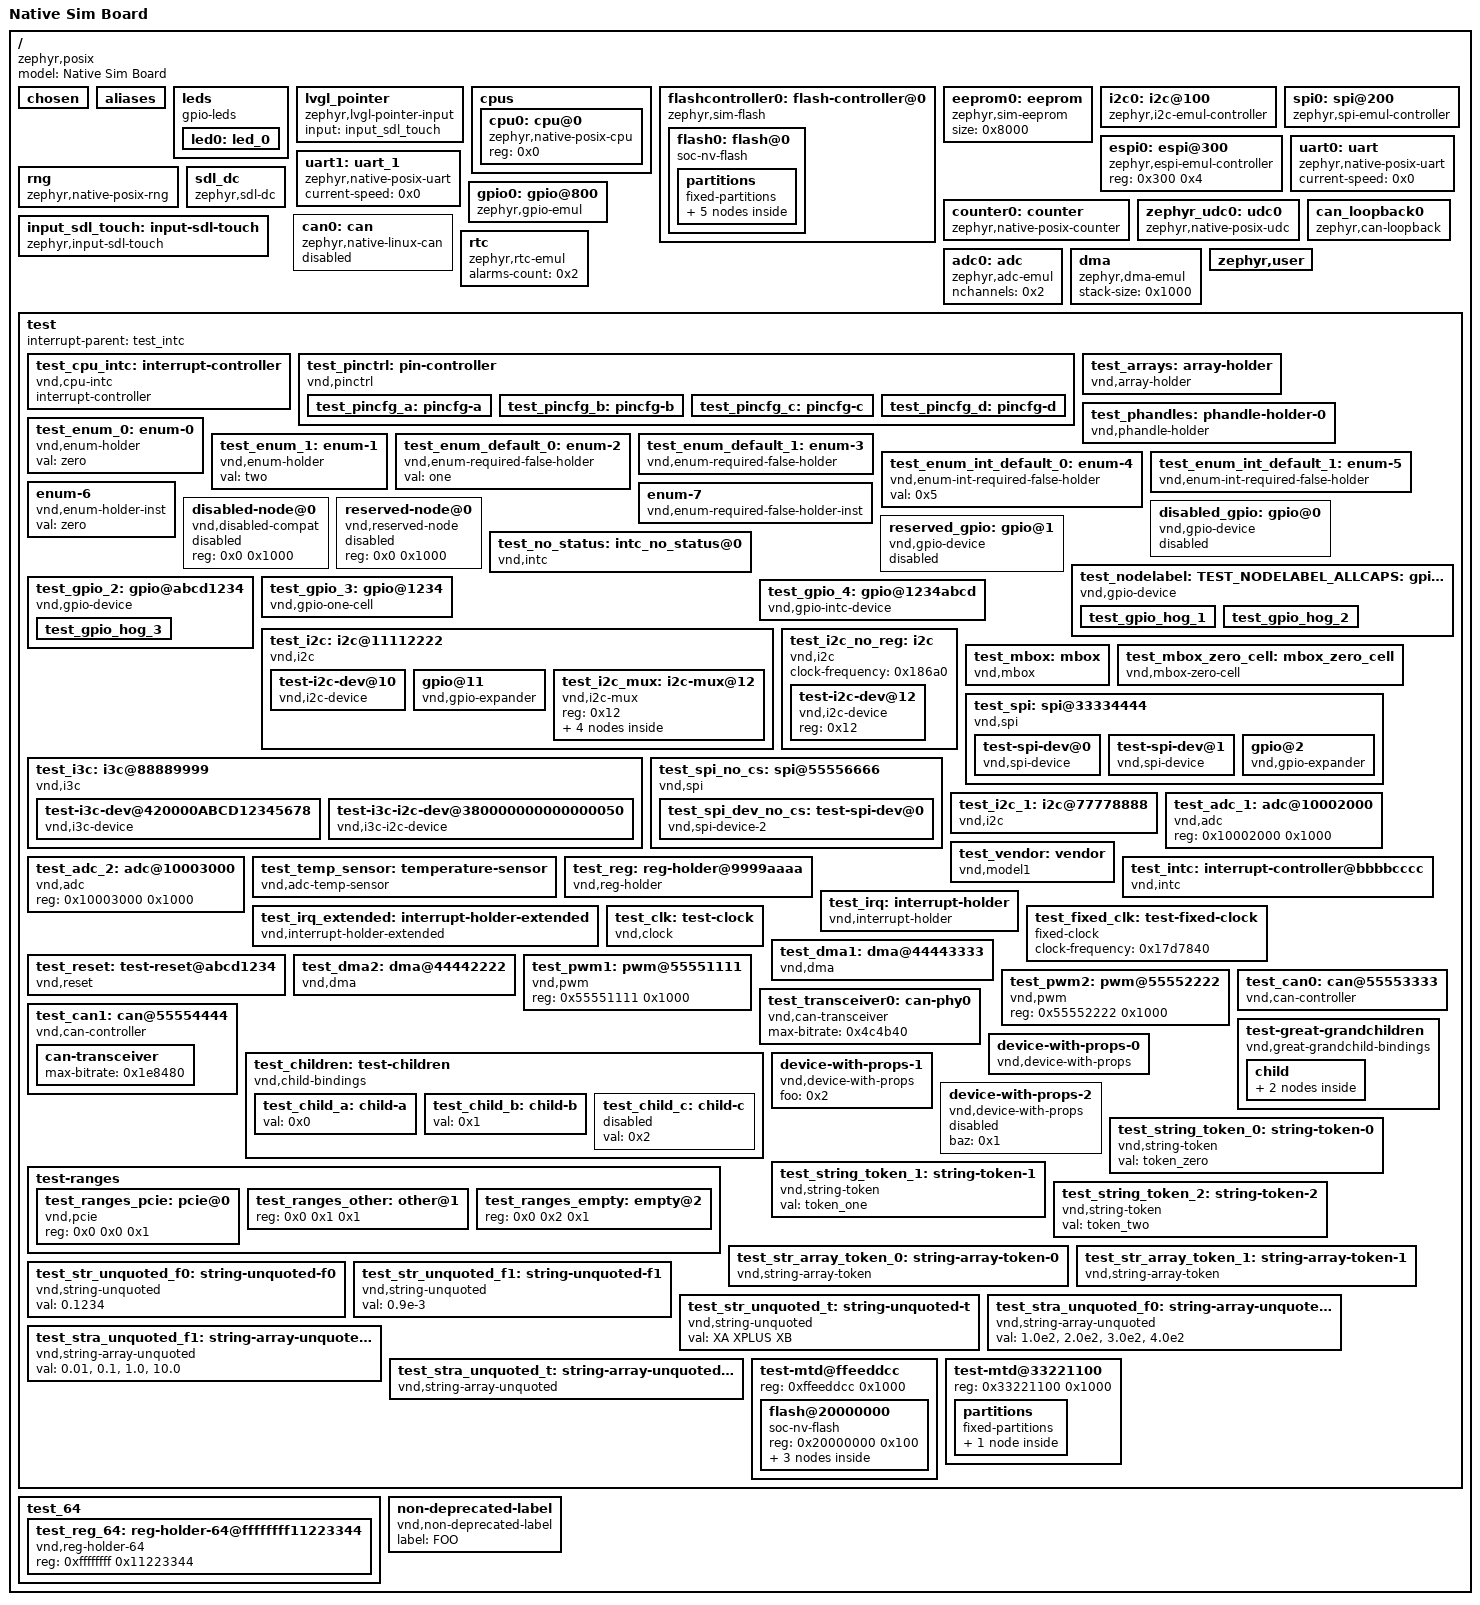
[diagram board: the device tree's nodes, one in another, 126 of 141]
/dts-v1/;

/ {
	#address-cells = < 0x1 >;
	#size-cells = < 0x1 >;
	model = "Native Sim Board";
	compatible = "zephyr,posix";
	chosen {
		zephyr,console = &uart0;
		zephyr,shell-uart = &uart0;
		zephyr,uart-mcumgr = &uart0;
		zephyr,flash = &flash0;
		zephyr,entropy = &rng;
		zephyr,flash-controller = &flashcontroller0;
		zephyr,display = &sdl_dc;
		zephyr,canbus = &can_loopback0;
		ztest,gpio = &test_nodelabel;
	};
	aliases {
		eeprom-0 = &eeprom0;
		i2c-0 = &i2c0;
		spi-0 = &spi0;
		led0 = &led0;
		rtc = &rtc;
		test-alias = &test_nodelabel;
	};
	leds {
		compatible = "gpio-leds";
		led0: led_0 {
			gpios = < &gpio0 0x0 0x0 >;
			label = "Green LED";
		};
	};
	lvgl_pointer {
		compatible = "zephyr,lvgl-pointer-input";
		input = < &input_sdl_touch >;
	};
	cpus {
		#address-cells = < 0x1 >;
		#size-cells = < 0x0 >;
		cpu0: cpu@0 {
			compatible = "zephyr,native-posix-cpu";
			reg = < 0x0 >;
		};
	};
	flashcontroller0: flash-controller@0 {
		compatible = "zephyr,sim-flash";
		reg = < 0x0 0x200000 >;
		#address-cells = < 0x1 >;
		#size-cells = < 0x1 >;
		erase-value = < 0xff >;
		flash0: flash@0 {
			status = "okay";
			compatible = "soc-nv-flash";
			erase-block-size = < 0x1000 >;
			write-block-size = < 0x1 >;
			reg = < 0x0 0x200000 >;
			partitions {
				compatible = "fixed-partitions";
				#address-cells = < 0x1 >;
				#size-cells = < 0x1 >;
				boot_partition: partition@0 {
					label = "mcuboot";
					reg = < 0x0 0xc000 >;
				};
				slot0_partition: partition@c000 {
					label = "image-0";
					reg = < 0xc000 0x69000 >;
				};
				slot1_partition: partition@75000 {
					label = "image-1";
					reg = < 0x75000 0x69000 >;
				};
				scratch_partition: partition@de000 {
					label = "image-scratch";
					reg = < 0xde000 0x1e000 >;
				};
				storage_partition: partition@fc000 {
					label = "storage";
					reg = < 0xfc000 0x4000 >;
				};
			};
		};
	};
	eeprom0: eeprom {
		status = "okay";
		compatible = "zephyr,sim-eeprom";
		size = < 0x8000 >;
	};
	i2c0: i2c@100 {
		status = "okay";
		compatible = "zephyr,i2c-emul-controller";
		clock-frequency = < 0x186a0 >;
		#address-cells = < 0x1 >;
		#size-cells = < 0x0 >;
		reg = < 0x100 0x4 >;
	};
	spi0: spi@200 {
		status = "okay";
		compatible = "zephyr,spi-emul-controller";
		clock-frequency = < 0x2faf080 >;
		#address-cells = < 0x1 >;
		#size-cells = < 0x0 >;
		reg = < 0x200 0x4 >;
	};
	espi0: espi@300 {
		status = "okay";
		compatible = "zephyr,espi-emul-controller";
		reg = < 0x300 0x4 >;
		#address-cells = < 0x1 >;
		#size-cells = < 0x0 >;
	};
	uart0: uart {
		status = "okay";
		compatible = "zephyr,native-posix-uart";
		current-speed = < 0x0 >;
	};
	uart1: uart_1 {
		status = "okay";
		compatible = "zephyr,native-posix-uart";
		current-speed = < 0x0 >;
	};
	rng: rng {
		status = "okay";
		compatible = "zephyr,native-posix-rng";
	};
	counter0: counter {
		status = "okay";
		compatible = "zephyr,native-posix-counter";
	};
	gpio0: gpio@800 {
		status = "okay";
		compatible = "zephyr,gpio-emul";
		reg = < 0x800 0x4 >;
		rising-edge;
		falling-edge;
		high-level;
		low-level;
		gpio-controller;
		#gpio-cells = < 0x2 >;
		phandle = < 0x1 >;
	};
	zephyr_udc0: udc0 {
		compatible = "zephyr,native-posix-udc";
	};
	sdl_dc: sdl_dc {
		compatible = "zephyr,sdl-dc";
		height = < 0xf0 >;
		width = < 0x140 >;
	};
	input_sdl_touch: input-sdl-touch {
		compatible = "zephyr,input-sdl-touch";
		phandle = < 0x2 >;
	};
	can_loopback0: can_loopback0 {
		status = "okay";
		compatible = "zephyr,can-loopback";
		sample-point = < 0x36b >;
		bus-speed = < 0x1e848 >;
	};
	can0: can {
		status = "disabled";
		compatible = "zephyr,native-linux-can";
		host-interface = "zcan0";
		sample-point = < 0x36b >;
		bus-speed = < 0x1e848 >;
	};
	rtc: rtc {
		status = "okay";
		compatible = "zephyr,rtc-emul";
		alarms-count = < 0x2 >;
	};
	adc0: adc {
		compatible = "zephyr,adc-emul";
		nchannels = < 0x2 >;
		#io-channel-cells = < 0x1 >;
		status = "okay";
	};
	dma: dma {
		compatible = "zephyr,dma-emul";
		#dma-cells = < 0x1 >;
		stack-size = < 0x1000 >;
	};
	zephyr,user {
		ph = < &test_gpio_1 >;
		string = "foo";
	};
	test {
		#address-cells = < 0x1 >;
		#size-cells = < 0x1 >;
		interrupt-parent = < &test_intc >;
		test_cpu_intc: interrupt-controller {
			compatible = "vnd,cpu-intc";
			#address-cells = < 0x0 >;
			#interrupt-cells = < 0x1 >;
			interrupt-controller;
			phandle = < 0x1a >;
		};
		test_pinctrl: pin-controller {
			compatible = "vnd,pinctrl";
			test_pincfg_a: pincfg-a {
				phandle = < 0x14 >;
			};
			test_pincfg_b: pincfg-b {
				phandle = < 0x15 >;
			};
			test_pincfg_c: pincfg-c {
				phandle = < 0x16 >;
			};
			test_pincfg_d: pincfg-d {
				phandle = < 0x17 >;
			};
		};
		test_arrays: array-holder {
			compatible = "vnd,array-holder", "vnd,undefined-compat";
			a = < 0x3e8 0x7d0 0xbb8 >;
			b = [ AA BB CC DD ];
			c = "bar", "baz";
		};
		test_phandles: phandle-holder-0 {
			compatible = "vnd,phandle-holder";
			ph = < &test_gpio_1 >;
			phs = < &test_i2c &test_spi >;
			phs-or = < &test_enum_default_0 &test_enum_default_1 >;
			gpios = < &test_gpio_1 0xa 0x14 >, < &test_gpio_2 0x1e 0x28 >;
			pha-gpios = < &test_gpio_1 0x32 0x3c >, < 0x0 >, < &test_gpio_3 0x46 >, < &test_gpio_2 0x50 0x5a >;
			foos = < &test_gpio_1 0x64 >, < &test_gpio_2 0x6e >;
			foo-names = "A", "b-c";
			pwms = < &test_pwm1 0x8 0xc8 0x3 >, < &test_pwm2 0x5 0x64 0x1 >;
			pwm-names = "red", "green";
			bar = < &test_gpio_1 0xc8 >, < &test_gpio_2 0xd2 >;
			baz-names = "john", "doe";
		};
		test_enum_0: enum-0 {
			compatible = "vnd,enum-holder";
			val = "zero";
		};
		test_enum_1: enum-1 {
			compatible = "vnd,enum-holder";
			val = "two";
		};
		test_enum_default_0: enum-2 {
			compatible = "vnd,enum-required-false-holder";
			val = "one";
			phandle = < 0x7 >;
		};
		test_enum_default_1: enum-3 {
			compatible = "vnd,enum-required-false-holder";
			phandle = < 0x8 >;
		};
		test_enum_int_default_0: enum-4 {
			compatible = "vnd,enum-int-required-false-holder";
			val = < 0x5 >;
		};
		test_enum_int_default_1: enum-5 {
			compatible = "vnd,enum-int-required-false-holder";
		};
		enum-6 {
			compatible = "vnd,enum-holder-inst";
			val = "zero";
		};
		enum-7 {
			compatible = "vnd,enum-required-false-holder-inst";
		};
		disabled-node@0 {
			compatible = "vnd,disabled-compat";
			reg = < 0x0 0x1000 >;
			status = "disabled";
		};
		reserved-node@0 {
			compatible = "vnd,reserved-node";
			reg = < 0x0 0x1000 >;
			status = "reserved";
		};
		disabled_gpio: gpio@0 {
			compatible = "vnd,gpio-device";
			gpio-controller;
			reg = < 0x0 0x1000 >;
			interrupts = < 0x3 0x1 >;
			#gpio-cells = < 0x2 >;
			status = "disabled";
		};
		reserved_gpio: gpio@1 {
			compatible = "vnd,gpio-device";
			gpio-controller;
			reg = < 0x1 0x1000 >;
			interrupts = < 0x3 0x1 >;
			#gpio-cells = < 0x2 >;
			label = "TEST_GPIO_1";
			status = "reserved";
		};
		test_no_status: intc_no_status@0 {
			compatible = "vnd,intc";
			reg = < 0x0 0x1000 >;
			interrupt-controller;
			#interrupt-cells = < 0x2 >;
		};
		test_nodelabel: TEST_NODELABEL_ALLCAPS: test_gpio_1: gpio@deadbeef {
			compatible = "vnd,gpio-device";
			gpio-controller;
			reg = < 0xdeadbeef 0x1000 >;
			#gpio-cells = < 0x2 >;
			#foo-cells = < 0x1 >;
			#baz-cells = < 0x1 >;
			label = "TEST_GPIO_1";
			interrupts = < 0x4 0x3 >;
			status = "okay";
			ngpios = < 0x64 >;
			phandle = < 0x3 >;
			test_gpio_hog_1 {
				gpio-hog;
				gpios = < 0x0 0x0 >, < 0x1 0x10 >;
				output-high;
			};
			test_gpio_hog_2 {
				gpio-hog;
				gpios = < 0x3 0x20 >;
				output-low;
			};
		};
		test_gpio_2: gpio@abcd1234 {
			compatible = "vnd,gpio-device";
			gpio-controller;
			reg = < 0xabcd1234 0x500 0x98765432 0xff >;
			reg-names = "one", "two";
			#gpio-cells = < 0x2 >;
			#foo-cells = < 0x1 >;
			#baz-cells = < 0x1 >;
			interrupts = < 0x5 0x2 >;
			label = "TEST_GPIO_2";
			status = "okay";
			ngpios = < 0xc8 >;
			phandle = < 0x9 >;
			test_gpio_hog_3 {
				gpio-hog;
				gpios = < 0x4 0x30 >;
				input;
				line-name = "TEST_GPIO_HOG_3";
			};
		};
		test_gpio_3: gpio@1234 {
			compatible = "vnd,gpio-one-cell";
			gpio-controller;
			reg = < 0x1234 0x500 >;
			#gpio-cells = < 0x1 >;
			status = "okay";
			phandle = < 0xa >;
		};
		test_gpio_4: gpio@1234abcd {
			compatible = "vnd,gpio-intc-device";
			reg = < 0x1234abcd 0x500 >;
			gpio-controller;
			#gpio-cells = < 0x2 >;
			interrupt-controller;
			#interrupt-cells = < 0x2 >;
			status = "okay";
			phandle = < 0x1b >;
		};
		test_i2c: i2c@11112222 {
			#address-cells = < 0x1 >;
			#size-cells = < 0x0 >;
			compatible = "vnd,i2c";
			reg = < 0x11112222 0x1000 >;
			label = "TEST_I2C_CTLR";
			status = "okay";
			clock-frequency = < 0x186a0 >;
			interrupts = < 0x6 0x2 0x7 0x1 >;
			interrupt-names = "status", "error";
			phandle = < 0x5 >;
			test-i2c-dev@10 {
				compatible = "vnd,i2c-device";
				label = "TEST_I2C_DEV_10";
				reg = < 0x10 >;
			};
			gpio@11 {
				gpio-controller;
				#gpio-cells = < 0x2 >;
				compatible = "vnd,gpio-expander";
				reg = < 0x11 >;
			};
			test_i2c_mux: i2c-mux@12 {
				compatible = "vnd,i2c-mux";
				reg = < 0x12 >;
				i2c-mux-ctlr-1 {
					compatible = "vnd,i2c-mux-controller";
					#address-cells = < 0x1 >;
					#size-cells = < 0x0 >;
					test_muxed_i2c_dev_1: muxed-i2c-dev@10 {
						compatible = "vnd,i2c-device";
						status = "disabled";
						reg = < 0x10 >;
					};
				};
				i2c-mux-ctlr-2 {
					compatible = "vnd,i2c-mux-controller";
					#address-cells = < 0x1 >;
					#size-cells = < 0x0 >;
					test_muxed_i2c_dev_2: muxed-i2c-dev@10 {
						compatible = "vnd,i2c-device";
						status = "disabled";
						reg = < 0x10 >;
					};
				};
			};
		};
		test_i2c_no_reg: i2c {
			#address-cells = < 0x1 >;
			#size-cells = < 0x0 >;
			compatible = "vnd,i2c";
			status = "okay";
			clock-frequency = < 0x186a0 >;
			test-i2c-dev@12 {
				compatible = "vnd,i2c-device";
				reg = < 0x12 >;
			};
		};
		test_i3c: i3c@88889999 {
			#address-cells = < 0x3 >;
			#size-cells = < 0x0 >;
			compatible = "vnd,i3c";
			reg = < 0x88889999 0x1000 >;
			label = "TEST_I3C_CTLR";
			status = "okay";
			test-i3c-dev@420000ABCD12345678 {
				compatible = "vnd,i3c-device";
				label = "TEST_I3C_DEV_42";
				reg = < 0x42 0xabcd 0x12345678 >;
			};
			test-i3c-i2c-dev@380000000000000050 {
				compatible = "vnd,i3c-i2c-device";
				label = "TEST_I3C_I2C_DEV_38";
				reg = < 0x38 0x0 0x50 >;
			};
		};
		test_mbox: mbox {
			compatible = "vnd,mbox";
			#mbox-cells = < 0x1 >;
			status = "okay";
			phandle = < 0x18 >;
		};
		test_mbox_zero_cell: mbox_zero_cell {
			compatible = "vnd,mbox-zero-cell";
			#mbox-cells = < 0x0 >;
			status = "okay";
			phandle = < 0x19 >;
		};
		test_spi: spi@33334444 {
			#address-cells = < 0x1 >;
			#size-cells = < 0x0 >;
			compatible = "vnd,spi";
			reg = < 0x33334444 0x1000 >;
			interrupts = < 0x8 0x3 0x9 0x0 0xa 0x1 >;
			label = "TEST_SPI_CTLR";
			status = "okay";
			clock-frequency = < 0x1e8480 >;
			cs-gpios = < &test_gpio_1 0x10 0x20 >, < &test_gpio_2 0x30 0x40 >, < &test_gpio_2 0x50 0x60 >;
			phandle = < 0x6 >;
			test-spi-dev@0 {
				compatible = "vnd,spi-device";
				label = "TEST_SPI_DEV_0";
				reg = < 0x0 >;
				spi-max-frequency = < 0x1e8480 >;
			};
			test-spi-dev@1 {
				compatible = "vnd,spi-device";
				reg = < 0x1 >;
				spi-max-frequency = < 0x1e8480 >;
			};
			gpio@2 {
				gpio-controller;
				#gpio-cells = < 0x2 >;
				compatible = "vnd,gpio-expander";
				reg = < 0x2 >;
				spi-max-frequency = < 0xf4240 >;
			};
		};
		test_spi_no_cs: spi@55556666 {
			#address-cells = < 0x1 >;
			#size-cells = < 0x0 >;
			compatible = "vnd,spi";
			reg = < 0x55556666 0x1000 >;
			status = "okay";
			clock-frequency = < 0x1e8480 >;
			test_spi_dev_no_cs: test-spi-dev@0 {
				compatible = "vnd,spi-device-2";
				reg = < 0x0 >;
				spi-max-frequency = < 0x1e8480 >;
			};
		};
		test_i2c_1: i2c@77778888 {
			#address-cells = < 0x1 >;
			#size-cells = < 0x0 >;
			compatible = "vnd,i2c";
			reg = < 0x77778888 0x1000 >;
			status = "okay";
			clock-frequency = < 0x186a0 >;
			interrupts = < 0xb 0x3 0xc 0x2 >;
			interrupt-names = "status", "error";
		};
		test_adc_1: adc@10002000 {
			reg = < 0x10002000 0x1000 >;
			compatible = "vnd,adc";
			status = "okay";
			#io-channel-cells = < 0x1 >;
			phandle = < 0xd >;
		};
		test_adc_2: adc@10003000 {
			reg = < 0x10003000 0x1000 >;
			compatible = "vnd,adc";
			status = "okay";
			#io-channel-cells = < 0x1 >;
			phandle = < 0xe >;
		};
		test_temp_sensor: temperature-sensor {
			compatible = "vnd,adc-temp-sensor";
			io-channels = < &test_adc_1 0xa >, < &test_adc_2 0x14 >;
			io-channel-names = "ch1", "ch2";
			dmas = < &test_dma1 0x1 0x2 >, < &test_dma2 0x3 0x4 >;
			dma-names = "tx", "rx";
			clocks = < &test_clk 0x3 0x7 >, < &test_fixed_clk >, < &test_clk 0x8 0x2 >;
			clock-names = "clk-a", "clk-fixed", "clk-b";
			resets = < &test_reset 0xa >, < &test_reset 0x14 >;
			reset-names = "reset-a", "reset-b";
			pinctrl-0 = < &test_pincfg_a &test_pincfg_b >;
			pinctrl-1 = < &test_pincfg_c &test_pincfg_d >;
			pinctrl-2 = < &test_pincfg_d >;
			pinctrl-names = "default", "sleep", "f.o.o2";
			mboxes = < &test_mbox 0x1 >, < &test_mbox 0x2 >, < &test_mbox_zero_cell >;
			mbox-names = "tx", "rx", "zero";
		};
		test_reg: reg-holder@9999aaaa {
			compatible = "vnd,reg-holder";
			reg = < 0x9999aaaa 0x1000 0xbbbbcccc 0x3f >;
			status = "okay";
			reg-names = "first", "second";
			misc-prop = < 0x4d2 >;
		};
		test_vendor: vendor {
			compatible = "vnd,model1", "gpio", "zephyr,model2";
			status = "okay";
		};
		test_intc: interrupt-controller@bbbbcccc {
			compatible = "vnd,intc";
			reg = < 0xbbbbcccc 0x1000 >;
			interrupt-controller;
			#interrupt-cells = < 0x2 >;
			interrupts = < 0xb 0x0 >;
			interrupt-parent = < &test_cpu_intc >;
			phandle = < 0x4 >;
		};
		test_irq: interrupt-holder {
			compatible = "vnd,interrupt-holder";
			status = "okay";
			interrupts = < 0x1e 0x3 0x28 0x5 0x3c 0x7 >;
			interrupt-parent = < &test_intc >;
			interrupt-names = "err", "stat", "done";
		};
		test_irq_extended: interrupt-holder-extended {
			compatible = "vnd,interrupt-holder-extended";
			status = "okay";
			interrupts-extended = < &test_intc 0x46 0x7 >, < &test_gpio_4 0x1e 0x3 >;
			interrupt-names = "int1", "int2";
		};
		test_fixed_clk: test-fixed-clock {
			compatible = "fixed-clock";
			clock-frequency = < 0x17d7840 >;
			#clock-cells = < 0x0 >;
			phandle = < 0x12 >;
		};
		test_clk: test-clock {
			compatible = "vnd,clock";
			#clock-cells = < 0x2 >;
			phandle = < 0x11 >;
		};
		test_reset: test-reset@abcd1234 {
			compatible = "vnd,reset";
			reg-width = < 0x4 >;
			reg = < 0xabcd1234 0x100 >;
			#reset-cells = < 0x1 >;
			phandle = < 0x13 >;
		};
		test_dma1: dma@44443333 {
			compatible = "vnd,dma";
			#dma-cells = < 0x2 >;
			reg = < 0x44443333 0x1000 >;
			interrupts = < 0xb 0x3 >;
			status = "okay";
			phandle = < 0xf >;
		};
		test_dma2: dma@44442222 {
			compatible = "vnd,dma";
			#dma-cells = < 0x2 >;
			reg = < 0x44442222 0x1000 >;
			interrupts = < 0xc 0x3 >;
			status = "okay";
			phandle = < 0x10 >;
		};
		test_pwm1: pwm@55551111 {
			compatible = "vnd,pwm";
			#pwm-cells = < 0x3 >;
			reg = < 0x55551111 0x1000 >;
			status = "okay";
			phandle = < 0xb >;
		};
		test_pwm2: pwm@55552222 {
			compatible = "vnd,pwm";
			#pwm-cells = < 0x3 >;
			reg = < 0x55552222 0x1000 >;
			status = "okay";
			phandle = < 0xc >;
		};
		test_transceiver0: can-phy0 {
			compatible = "vnd,can-transceiver";
			status = "okay";
			#phy-cells = < 0x0 >;
			max-bitrate = < 0x4c4b40 >;
			phandle = < 0x1c >;
		};
		test_can0: can@55553333 {
			compatible = "vnd,can-controller";
			reg = < 0x55553333 0x1000 >;
			sample-point = < 0x36b >;
			bus-speed = < 0x1e848 >;
			status = "okay";
			phys = < &test_transceiver0 >;
		};
		test_can1: can@55554444 {
			compatible = "vnd,can-controller";
			reg = < 0x55554444 0x1000 >;
			sample-point = < 0x36b >;
			bus-speed = < 0x1e848 >;
			status = "okay";
			can-transceiver {
				max-bitrate = < 0x1e8480 >;
			};
		};
		test_children: test-children {
			compatible = "vnd,child-bindings";
			test_child_a: child-a {
				val = < 0x0 >;
				status = "okay";
			};
			test_child_b: child-b {
				val = < 0x1 >;
				status = "okay";
			};
			test_child_c: child-c {
				val = < 0x2 >;
				status = "disabled";
			};
		};
		test-great-grandchildren {
			compatible = "vnd,great-grandchild-bindings";
			child {
				grandchild {
					test_ggc: great-grandchild {
						ggc-prop = < 0x2a >;
					};
				};
			};
		};
		test-ranges {
			#address-cells = < 0x2 >;
			#size-cells = < 0x1 >;
			test_ranges_pcie: pcie@0 {
				compatible = "vnd,pcie";
				reg = < 0x0 0x0 0x1 >;
				#address-cells = < 0x3 >;
				#size-cells = < 0x2 >;
				ranges = < 0x1000000 0x0 0x0 0x0 0x3eff0000 0x0 0x10000 >, < 0x2000000 0x0 0x10000000 0x0 0x10000000 0x0 0x2eff0000 >, < 0x3000000 0x80 0x0 0x80 0x0 0x80 0x0 >;
			};
			test_ranges_other: other@1 {
				reg = < 0x0 0x1 0x1 >;
				#address-cells = < 0x2 >;
				#size-cells = < 0x1 >;
				ranges = < 0x0 0x0 0x0 0x3eff0000 0x10000 >, < 0x0 0x10000000 0x0 0x10000000 0x2eff0000 >;
			};
			test_ranges_empty: empty@2 {
				reg = < 0x0 0x2 0x1 >;
				#address-cells = < 0x2 >;
				#size-cells = < 0x1 >;
				ranges;
			};
		};
		device-with-props-0 {
			compatible = "vnd,device-with-props";
			status = "okay";
			foo = < 0x1 >;
			bar = < 0x2 >;
		};
		device-with-props-1 {
			compatible = "vnd,device-with-props";
			status = "okay";
			foo = < 0x2 >;
		};
		device-with-props-2 {
			compatible = "vnd,device-with-props";
			status = "disabled";
			baz = < 0x1 >;
		};
		test_string_token_0: string-token-0 {
			compatible = "vnd,string-token";
			val = "token_zero";
		};
		test_string_token_1: string-token-1 {
			compatible = "vnd,string-token";
			val = "token_one";
		};
		test_string_token_2: string-token-2 {
			compatible = "vnd,string-token";
			val = "token_two";
		};
		test_str_array_token_0: string-array-token-0 {
			compatible = "vnd,string-array-token";
			val = "token_first_idx_zero", "token_first_idx_one", "token_first_idx_two";
		};
		test_str_array_token_1: string-array-token-1 {
			compatible = "vnd,string-array-token";
			val = "token_second_idx_zero", "token_second_idx_one", "token_second_idx_two", "token_second_idx_three";
		};
		test_str_unquoted_f0: string-unquoted-f0 {
			compatible = "vnd,string-unquoted";
			val = "0.1234";
		};
		test_str_unquoted_f1: string-unquoted-f1 {
			compatible = "vnd,string-unquoted";
			val = "0.9e-3";
		};
		test_str_unquoted_t: string-unquoted-t {
			compatible = "vnd,string-unquoted";
			val = "XA XPLUS XB";
		};
		test_stra_unquoted_f0: string-array-unquoted-f0 {
			compatible = "vnd,string-array-unquoted";
			val = "1.0e2", "2.0e2", "3.0e2", "4.0e2";
		};
		test_stra_unquoted_f1: string-array-unquoted-f1 {
			compatible = "vnd,string-array-unquoted";
			val = "0.01", "0.1", "1.0", "10.0";
		};
		test_stra_unquoted_t: string-array-unquoted-t {
			compatible = "vnd,string-array-unquoted";
			val = "XA XPLUS XB", "XC XPLUS XD", "XA XMINUS XB", "XC XMINUS XD";
		};
		test-mtd@ffeeddcc {
			reg = < 0xffeeddcc 0x1000 >;
			#address-cells = < 0x1 >;
			#size-cells = < 0x1 >;
			flash@20000000 {
				compatible = "soc-nv-flash";
				reg = < 0x20000000 0x100 >;
				partitions {
					compatible = "fixed-partitions";
					#address-cells = < 0x1 >;
					#size-cells = < 0x1 >;
					partition@0 {
						reg = < 0x0 0xc0 >;
						label = "test-partition-0";
					};
					partition@c0 {
						reg = < 0xc0 0x40 >;
						label = "test-partition-1";
					};
				};
			};
		};
		test-mtd@33221100 {
			reg = < 0x33221100 0x1000 >;
			partitions {
				compatible = "fixed-partitions";
				#address-cells = < 0x1 >;
				#size-cells = < 0x1 >;
				partition@6ff80 {
					reg = < 0x6ff80 0x80 >;
					label = "test-partition-2";
				};
			};
		};
	};
	test_64 {
		#address-cells = < 0x2 >;
		#size-cells = < 0x0 >;
		test_reg_64: reg-holder-64@ffffffff11223344 {
			compatible = "vnd,reg-holder-64";
			reg = < 0xffffffff 0x11223344 >;
			status = "okay";
			reg-names = "test_name";
		};
	};
	non-deprecated-label {
		compatible = "vnd,non-deprecated-label";
		label = "FOO";
	};
};
